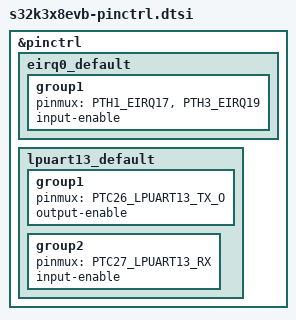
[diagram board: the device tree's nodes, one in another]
/*
 * Copyright 2026 NXP
 *
 * SPDX-License-Identifier: Apache-2.0
 */

#include <nxp/s32/S32K358_K348_K338_K328_289BGA-pinctrl.h>

&pinctrl {
	eirq0_default: eirq0_default {
		group1 {
			pinmux = <PTH1_EIRQ17>, <PTH3_EIRQ19>;
			input-enable;
		};
	};

	lpuart13_default: lpuart13_default {
		group1 {
			pinmux = <PTC26_LPUART13_TX_O>;
			output-enable;
		};

		group2 {
			pinmux = <PTC27_LPUART13_RX>;
			input-enable;
		};
	};
};
